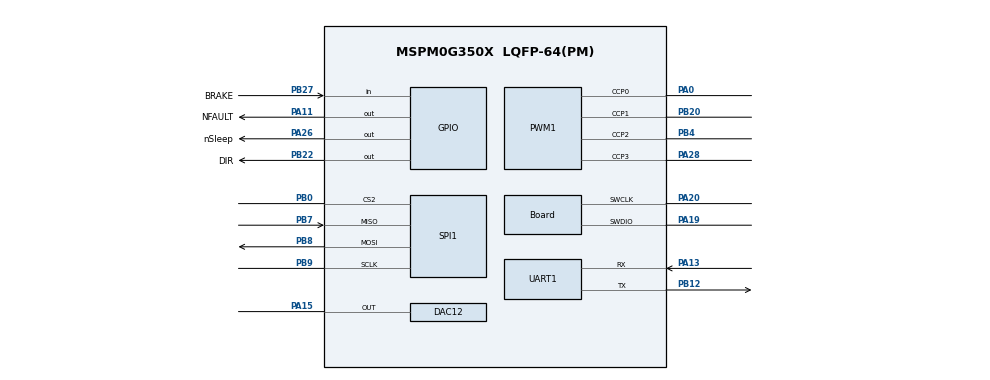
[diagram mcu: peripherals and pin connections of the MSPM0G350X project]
//@cliArgs --device "MSPM0G350X" --package "LQFP-64(PM)" --part "Default"
// @cliArgs --board /ti/boards/LP_MSPM0G3507 --rtos nortos

/**
 * Import the modules used in this configuration.
 */
const ADC12         = scripting.addModule("/ti/driverlib/ADC12", {}, false);
const ADC121        = ADC12.addInstance();
const ADC122        = ADC12.addInstance();
const Board         = scripting.addModule("/ti/driverlib/Board");
const CAPTURE       = scripting.addModule("/ti/driverlib/CAPTURE", {}, false);
const CAPTURE1      = CAPTURE.addInstance();
const COMP          = scripting.addModule("/ti/driverlib/COMP", {}, false);
const COMP1         = COMP.addInstance();
const COMP2         = COMP.addInstance();
const COMP3         = COMP.addInstance();
const CRC           = scripting.addModule("/ti/driverlib/CRC");
const DAC12         = scripting.addModule("/ti/driverlib/DAC12");
const GPIO          = scripting.addModule("/ti/driverlib/GPIO", {}, false);
const GPIO1         = GPIO.addInstance();
const GPIO2         = GPIO.addInstance();
const MATHACL       = scripting.addModule("/ti/driverlib/MATHACL");
const PWM           = scripting.addModule("/ti/driverlib/PWM", {}, false);
const PWM1          = PWM.addInstance();
const SPI           = scripting.addModule("/ti/driverlib/SPI", {}, false);
const SPI1          = SPI.addInstance();
const SYSCTL        = scripting.addModule("/ti/driverlib/SYSCTL");
const TIMER         = scripting.addModule("/ti/driverlib/TIMER", {}, false);
const TIMER1        = TIMER.addInstance();
const TIMERFault    = scripting.addModule("/ti/driverlib/TIMERFault", {}, false);
const TIMERFault1   = TIMERFault.addInstance();
const UART          = scripting.addModule("/ti/driverlib/UART", {}, false);
const UART1         = UART.addInstance();
const ProjectConfig = scripting.addModule("/ti/project_config/ProjectConfig");

/**
 * Write custom configuration values to the imported modules.
 */
ProjectConfig.genDisable = true;

ADC121.$name                      = "ADC0";
ADC121.sampClkSrc                 = "DL_ADC12_CLOCK_ULPCLK";
ADC121.samplingOperationMode      = "sequence";
ADC121.repeatMode                 = true;
ADC121.trigSrc                    = "DL_ADC12_TRIG_SRC_EVENT";
ADC121.powerDownMode              = "DL_ADC12_POWER_DOWN_MODE_MANUAL";
ADC121.adcMem3trig                = "DL_ADC12_TRIGGER_MODE_TRIGGER_NEXT";
ADC121.adcMem2trig                = "DL_ADC12_TRIGGER_MODE_TRIGGER_NEXT";
ADC121.adcMem2chansel             = "DL_ADC12_INPUT_CHAN_2";
ADC121.endAdd                     = 1;
ADC121.subChanID                  = 12;
ADC121.adcMem1trig                = "DL_ADC12_TRIGGER_MODE_TRIGGER_NEXT";
ADC121.adcMem0avgen               = true;
ADC121.adcMem1avgen               = true;
ADC121.adcMem0chansel             = "DL_ADC12_INPUT_CHAN_3";
ADC121.adcMem1chansel             = "DL_ADC12_INPUT_CHAN_2";
ADC121.enabledInterrupts          = ["DL_ADC12_INTERRUPT_MEM1_RESULT_LOADED"];
ADC121.interruptPriority          = "0";
ADC121.sampleTime0                = "250ns";
ADC121.sampleTime1                = "250ns";
ADC121.hwNumerator                = "DL_ADC12_HW_AVG_NUM_ACC_8";
ADC121.hwDenominator              = "DL_ADC12_HW_AVG_DEN_DIV_BY_8";
ADC121.peripheral.$assign         = "ADC0";
ADC121.peripheral.adcPin3.$assign = "PA24";
ADC121.peripheral.adcPin2.$assign = "PA25";

ADC122.$name                      = "ADC1";
ADC122.sampClkSrc                 = "DL_ADC12_CLOCK_ULPCLK";
ADC122.samplingOperationMode      = "sequence";
ADC122.repeatMode                 = true;
ADC122.trigSrc                    = "DL_ADC12_TRIG_SRC_EVENT";
ADC122.subChanID                  = 12;
ADC122.adcMem2trig                = "DL_ADC12_TRIGGER_MODE_TRIGGER_NEXT";
ADC122.powerDownMode              = "DL_ADC12_POWER_DOWN_MODE_MANUAL";
ADC122.adcMem0avgen               = true;
ADC122.adcMem1avgen               = true;
ADC122.adcMem2avgen               = true;
ADC122.adcMem0chansel             = "DL_ADC12_INPUT_CHAN_2";
ADC122.adcMem1chansel             = "DL_ADC12_INPUT_CHAN_3";
ADC122.adcMem2chansel             = "DL_ADC12_INPUT_CHAN_6";
ADC122.adcMem1trig                = "DL_ADC12_TRIGGER_MODE_TRIGGER_NEXT";
ADC122.endAdd                     = 1;
ADC122.sampleTime0                = "250ns";
ADC122.sampleTime1                = "250ns";
ADC122.hwNumerator                = "DL_ADC12_HW_AVG_NUM_ACC_8";
ADC122.hwDenominator              = "DL_ADC12_HW_AVG_DEN_DIV_BY_8";
ADC122.peripheral.$assign         = "ADC1";
ADC122.peripheral.adcPin2.$assign = "PA17";
ADC122.peripheral.adcPin3.$assign = "PA18";

Board.peripheral.$assign          = "DEBUGSS";
Board.peripheral.swclkPin.$assign = "PA20";
Board.peripheral.swdioPin.$assign = "PA19";

CAPTURE1.timerStartTimer      = true;
CAPTURE1.captSelect           = "Trigger";
CAPTURE1.subscriberPort       = "FSUB0";
CAPTURE1.multi_ch0_input_mode = "DL_TIMER_CC_IN_SEL_FSUB0";
CAPTURE1.multi_ch_zero        = 0;
CAPTURE1.ccIndexMulti         = [0];
CAPTURE1.subscriberChannel    = 1;
CAPTURE1.timerPeriod          = "800us";
CAPTURE1.$name                = "CAPTURE";
CAPTURE1.interrupts           = ["CC0_DN","ZERO"];
CAPTURE1.peripheral.$assign   = "TIMA1";

COMP1.vSource                               = "DL_COMP_REF_SOURCE_VDDA_DAC";
COMP1.terminalSelect                        = "DL_COMP_REF_TERMINAL_SELECT_NEG";
COMP1.posChannel                            = "DL_COMP_IPSEL_CHANNEL_2";
COMP1.negChannel                            = "DL_COMP_IMSEL_CHANNEL_1";
COMP1.channelEnable                         = ["POS"];
COMP1.controlSelect                         = "DL_COMP_DAC_CONTROL_SW";
COMP1.pubChanID                             = 1;
COMP1.hysteresis                            = "DL_COMP_HYSTERESIS_30";
COMP1.enableOutputFilter                    = true;
COMP1.$name                                 = "COMP_U";
COMP1.outputInterruptEdge                   = "DL_COMP_OUTPUT_INT_EDGE_FALLING";
COMP1.enabledEvents                         = ["DL_COMP_EVENT_OUTPUT_EDGE"];
COMP1.selectOutputFilter                    = "DL_COMP_FILTER_DELAY_2700";
COMP1.peripheral.$assign                    = "COMP0";
COMP1.peripheral.compPinPos2.$assign        = "PA14";
COMP1.compPinPos2Config.hideOutputInversion = scripting.forceWrite(false);

COMP2.channelEnable                         = ["POS"];
COMP2.vSource                               = "DL_COMP_REF_SOURCE_VDDA_DAC";
COMP2.terminalSelect                        = "DL_COMP_REF_TERMINAL_SELECT_NEG";
COMP2.controlSelect                         = "DL_COMP_DAC_CONTROL_SW";
COMP2.pubChanID                             = 2;
COMP2.enabledEvents                         = ["DL_COMP_EVENT_OUTPUT_EDGE"];
COMP2.enableOutputFilter                    = true;
COMP2.hysteresis                            = "DL_COMP_HYSTERESIS_30";
COMP2.outputInterruptEdge                   = "DL_COMP_OUTPUT_INT_EDGE_FALLING";
COMP2.$name                                 = "COMP_V";
COMP2.selectOutputFilter                    = "DL_COMP_FILTER_DELAY_2700";
COMP2.peripheral.$assign                    = "COMP1";
COMP2.peripheral.compPinPos0.$assign        = "PB26";
COMP2.compPinPos0Config.hideOutputInversion = scripting.forceWrite(false);

COMP3.channelEnable                         = ["POS"];
COMP3.vSource                               = "DL_COMP_REF_SOURCE_VDDA_DAC";
COMP3.terminalSelect                        = "DL_COMP_REF_TERMINAL_SELECT_NEG";
COMP3.controlSelect                         = "DL_COMP_DAC_CONTROL_SW";
COMP3.pubChanID                             = 3;
COMP3.enabledEvents                         = ["DL_COMP_EVENT_OUTPUT_EDGE"];
COMP3.enableOutputFilter                    = true;
COMP3.hysteresis                            = "DL_COMP_HYSTERESIS_30";
COMP3.outputInterruptEdge                   = "DL_COMP_OUTPUT_INT_EDGE_FALLING";
COMP3.$name                                 = "COMP_W";
COMP3.selectOutputFilter                    = "DL_COMP_FILTER_DELAY_2700";
COMP3.peripheral.$assign                    = "COMP2";
COMP3.peripheral.compPinPos0.$assign        = "PB21";
COMP3.compPinPos0Config.hideOutputInversion = scripting.forceWrite(false);

CRC.polynomial = "16_POLYNOMIAL";
CRC.seed       = 0xFFFF;

DAC12.dacOutputPinEn            = true;
DAC12.dacSampleTimerEn          = true;
DAC12.dacSampleTimerRate        = "100K";
DAC12.dacAmplifier              = "ON";
DAC12.dacEnable                 = false;
DAC12.peripheral.$assign        = "DAC0";
DAC12.peripheral.OutPin.$assign = "PA15";

GPIO1.$name                              = "FOC_GPIO_OUT";
GPIO1.associatedPins.create(2);
GPIO1.associatedPins[0].$name            = "NFAULT";
GPIO1.associatedPins[0].internalResistor = "PULL_UP";
GPIO1.associatedPins[0].pin.$assign      = "PA11";
GPIO1.associatedPins[1].$name            = "nSleep";
GPIO1.associatedPins[1].initialValue     = "SET";
GPIO1.associatedPins[1].pin.$assign      = "PA26";

GPIO2.$name                         = "FOC_GPIO_IN";
GPIO2.associatedPins.create(2);
GPIO2.associatedPins[0].direction   = "INPUT";
GPIO2.associatedPins[0].$name       = "BRAKE";
GPIO2.associatedPins[0].pin.$assign = "PB27";
GPIO2.associatedPins[1].$name       = "DIR";
GPIO2.associatedPins[1].pin.$assign = "PB22";

PWM1.pwmMode                                 = "CENTER_ALIGN";
PWM1.deadBandEn                              = true;
PWM1.dbRiseDelayTimerCount                   = 32;
PWM1.dbFallDelayTimerCount                   = 32;
PWM1.dbInsertionMode                         = "Mode1";
PWM1.ccIndexCmpl                             = [1,2,3];
PWM1.enableShadowLoad                        = true;
PWM1.timerStartTimer                         = true;
PWM1.faultConditionDuration                  = "FL_LATCH_SW_CLR";
PWM1.faultInput                              = "FI_DEPENDENT";
PWM1.faultInputEn                            = "FIEN_ENABLED";
PWM1.faultInputFilterEn                      = true;
PWM1.faultChannel1BehaviorEntry              = "LOW";
PWM1.faultChannel1BehaviorExit               = "LOW";
PWM1.faultChannel2BehaviorEntry              = "LOW";
PWM1.faultChannel2BehaviorExit               = "LOW";
PWM1.faultChannel3BehaviorEntry              = "LOW";
PWM1.faultChannel3BehaviorExit               = "LOW";
PWM1.faultInputDetect                        = true;
PWM1.faultFilterSamplePeriod                 = "8";
PWM1.event1PublisherChannel                  = 12;
PWM1.ccIndex                                 = [0,1,2,3];
PWM1.timerCount                              = 8000;
PWM1.enableRepeatCounter                     = true;
PWM1.faultChannel0BehaviorEntry              = "LOW";
PWM1.faultChannel0BehaviorExit               = "LOW";
PWM1.$name                                   = "PWMA0";
PWM1.faultTimerCountExit                     = "FAULT_EXIT_CTR_CVAE_ACTION";
PWM1.event1ControllerInterruptEn             = ["CC0_DN_EVENT"];
PWM1.event2ControllerInterruptEn             = ["CC0_DN_EVENT"];
PWM1.faultSource                             = ["2"];
PWM1.faultHandlerEn                          = true;
PWM1.peripheral.$assign                      = "TIMA0";
PWM1.peripheral.ccp0Pin.$assign              = "PA0";
PWM1.peripheral.ccp1Pin.$assign              = "PB20";
PWM1.peripheral.ccp1Pin_cmpl.$assign         = "PB13";
PWM1.peripheral.ccp2Pin.$assign              = "PB4";
PWM1.peripheral.ccp2Pin_cmpl.$assign         = "PB1";
PWM1.peripheral.ccp3Pin.$assign              = "PA28";
PWM1.peripheral.ccp3Pin_cmpl.$assign         = "PA31";
PWM1.PWM_CHANNEL_0.$name                     = "ti_driverlib_pwm_PWMTimerCC1";
PWM1.PWM_CHANNEL_1.$name                     = "ti_driverlib_pwm_PWMTimerCC2";
PWM1.PWM_CHANNEL_1.shadowUpdateMode          = "ZERO_EVT";
PWM1.PWM_CHANNEL_2.$name                     = "ti_driverlib_pwm_PWMTimerCC6";
PWM1.PWM_CHANNEL_2.shadowUpdateMode          = "ZERO_EVT";
PWM1.PWM_CHANNEL_3.$name                     = "ti_driverlib_pwm_PWMTimerCC0";
PWM1.PWM_CHANNEL_3.shadowUpdateMode          = "ZERO_EVT";

SPI1.$name                      = "SPI_0";
SPI1.targetBitRate              = 5000000;
SPI1.phase                      = "1";
SPI1.dataSize                   = 16;
SPI1.chipSelect                 = ["2"];
SPI1.peripheral.$assign         = "SPI1";
SPI1.peripheral.sclkPin.$assign = "PB9";
SPI1.peripheral.mosiPin.$assign = "PB8";
SPI1.peripheral.misoPin.$assign = "PB7";
SPI1.peripheral.cs2Pin.$assign  = "PB0";

SYSCTL.SYSPLL_CLK2XEn     = true;
SYSCTL.SYSPLL_Pdiv        = 1;
SYSCTL.SYSPLL_Qdiv        = 5;
SYSCTL.SYSPLL_CLK2XDiv    = 3;
SYSCTL.MCLKSource         = "HSCLK";
SYSCTL.HSCLKSource        = "SYSPLLCLK2X";
SYSCTL.validateClkStatus  = true;
SYSCTL.MFPCLKEn           = true;
SYSCTL.UDIV               = "2";
SYSCTL.peripheral.$assign = "SYSCTL";

TIMER1.$name              = "FOC_TIMG0";
TIMER1.timerPeriod        = "1 ms";
TIMER1.timerMode          = "PERIODIC";
TIMER1.timerStartTimer    = true;
TIMER1.interrupts         = ["LOAD"];
TIMER1.peripheral.$assign = "TIMG0";

PWM1.associatedFault              = TIMERFault1;
TIMERFault1.$name                 = "FOC_TIM_FAULT";
TIMERFault1.enabledFaults         = ["2"];
TIMERFault1.faultPin2.$assign     = "PA27";

UART1.$name                               = "UART_0";
UART1.targetBaudRate                      = 115200;
UART1.enableFIFO                          = true;
UART1.rxFifoThreshold                     = "DL_UART_RX_FIFO_LEVEL_ONE_ENTRY";
UART1.txFifoThreshold                     = "DL_UART_TX_FIFO_LEVEL_EMPTY";
UART1.enabledDMATXTriggers                = "DL_UART_DMA_INTERRUPT_TX";
UART1.enabledDMARXTriggers                = "DL_UART_DMA_INTERRUPT_RX";
UART1.peripheral.$assign                  = "UART3";
UART1.peripheral.rxPin.$assign            = "PA13";
UART1.peripheral.txPin.$assign            = "PB12";
UART1.DMA_CHANNEL_TX.$name                = "DMA_CH1";
UART1.DMA_CHANNEL_TX.addressMode          = "b2f";
UART1.DMA_CHANNEL_TX.srcLength            = "BYTE";
UART1.DMA_CHANNEL_TX.dstLength            = "BYTE";
UART1.DMA_CHANNEL_TX.srcIncrement         = "INCREMENT";
UART1.DMA_CHANNEL_TX.enableInterrupt      = true;
UART1.DMA_CHANNEL_TX.peripheral.$assign   = "DMA_CH1";
UART1.DMA_CHANNEL_RX.$name                = "DMA_CH0";
UART1.DMA_CHANNEL_RX.addressMode          = "f2b";
UART1.DMA_CHANNEL_RX.srcLength            = "BYTE";
UART1.DMA_CHANNEL_RX.dstLength            = "BYTE";
UART1.DMA_CHANNEL_RX.destIncrement        = "INCREMENT";
UART1.DMA_CHANNEL_RX.enableEarlyInterrupt = true;
UART1.DMA_CHANNEL_RX.earlyIntThresh       = "64";
UART1.DMA_CHANNEL_RX.peripheral.$assign   = "DMA_CH0";
